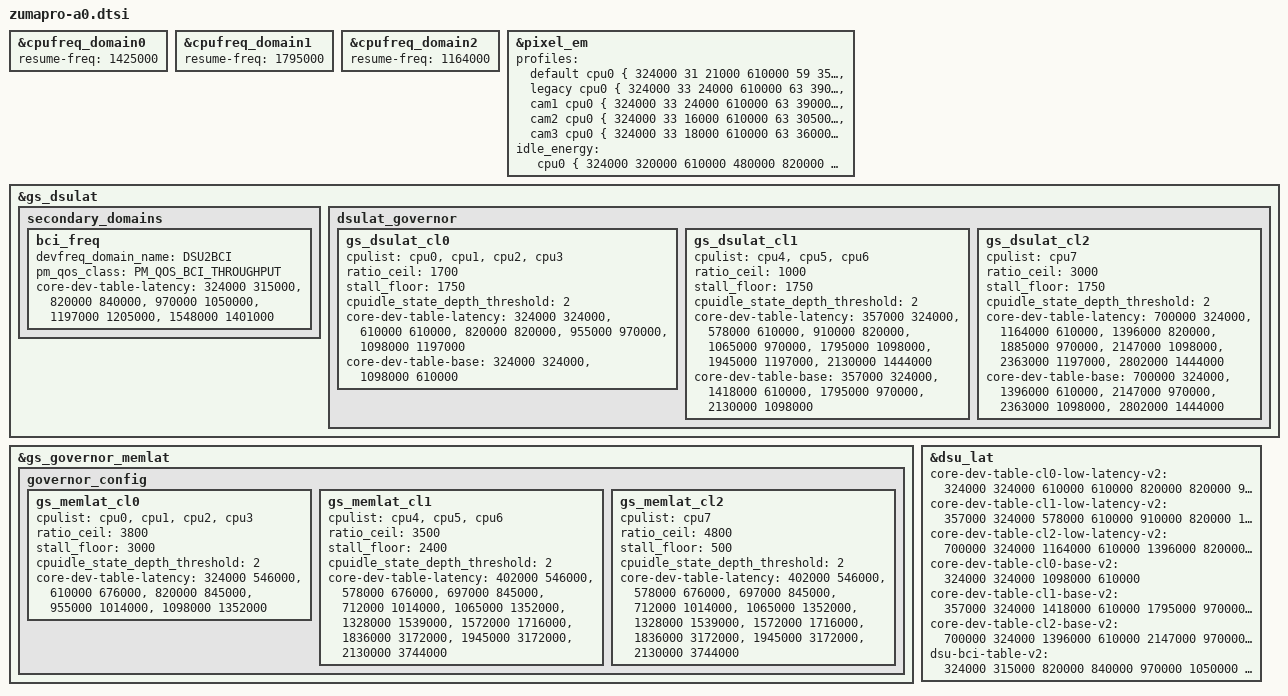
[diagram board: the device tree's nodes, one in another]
// SPDX-License-Identifier: GPL-2.0-only
/*
 * Copyright 2021 Google LLC.
 *
 */

#include "zumapro.dtsi"

&cpufreq_domain0 {
	resume-freq = <1425000>;
};

&cpufreq_domain1 {
	resume-freq = <1795000>;
};

&cpufreq_domain2 {
	resume-freq = <1164000>;
};

&pixel_em {
		profiles =
			"default
				cpu0 {
				324000 31 21000
				610000 59 35000
				820000 79 50000
				955000 92 60000
				1098000 106 74000
				1197000 116 85000
				1328000 128 99000
				1425000 138 116000
				1548000 150 131000
				1696000 164 156000
				1849000 179 193000
				1950000 189 226000
				}
				cpu4 {
				357000 100 53000
				578000 162 88000
				648000 182 99000
				787000 221 130000
				910000 256 162000
				1065000 299 205000
				1221000 343 263000
				1328000 373 308000
				1418000 399 347000
				1549000 435 400000
				1795000 504 526000
				1945000 547 660000
				2130000 599 843000
				2245000 632 1034000
				2367000 666 1221000
				2450000 689 1380000
				2600000 731 1722000
				}
				cpu7 {
				700000 226 250000
				1164000 378 536000
				1396000 429 732000
				1557000 522 912000
				1745000 572 1116000
				1885000 603 1286000
				1999000 674 1527000
				2147000 712 1929000
				2294000 746 2513000
				2363000 777 2808000
				2499000 822 3533000
				2687000 885 4854000
				2802000 923 5894000
				2914000 960 7122000
				2943000 970 7480000
				2970000 979 7828000
				3015000 994 8447000
				3105000 1024 9833000
				}
			",
			"legacy
				cpu0 {
				324000 33 24000
				610000 63 39000
				820000 84 56000
				955000 100 73000
				1098000 113 86000
				1197000 123 98000
				1328000 136 116000
				1425000 152 141000
				1548000 159 158000
				1696000 175 198000
				1849000 189 242000
				1950000 201 289000
				}
				cpu4 {
				357000 118 56000
				578000 170 84000
				648000 205 105000
				787000 212 107000
				910000 268 148000
				1065000 318 201000
				1221000 359 251000
				1328000 405 304000
				1418000 439 356000
				1549000 456 405000
				1795000 478 439000
				1945000 540 596000
				2130000 588 743000
				2245000 629 930000
				2367000 661 1122000
				2450000 692 1314000
				2600000 721 1515000
				}
				cpu7 {
				7000000 235 190000
				1164000 399 342000
				1396000 443 415000
				1557000 507 544000
				1745000 571 682000
				1885000 609 765000
				1999000 618 799000
				2147000 680 983000
				2294000 714 1134000
				2363000 748 1322000
				2499000 794 1481000
				2687000 850 1883000
				2802000 923 2377000
				2914000 972 2882000
				2943000 999 3465000
				2970000 1007 3954000
				3015000 1014 4200000
				3105000 1024 4500000
				}
			",
			"cam1
				cpu0 {
				324000 33 24000
				610000 63 39000
				820000 84 56000
				955000 100 73000
				1098000 113 86000
				1197000 123 98000
				1328000 136 116000
				1425000 152 141000
				1548000 159 158000
				1696000 175 198000
				1849000 189 242000
				1950000 201 289000
				}
				cpu4 {
				357000 118 56000
				578000 170 84000
				648000 205 105000
				787000 212 107000
				910000 268 148000
				1065000 318 201000
				1221000 359 251000
				1328000 405 304000
				1418000 439 356000
				1549000 456 405000
				1795000 478 439000
				1945000 540 596000
				2130000 588 743000
				2245000 629 930000
				2367000 661 1122000
				2450000 692 1314000
				2600000 721 1515000
				}
				cpu7 {
				700000 235 190000
				1164000 399 342000
				1396000 443 415000
				1557000 507 544000
				1745000 571 682000
				1885000 609 765000
				1999000 618 799000
				2147000 680 983000
				2294000 714 1134000
				2363000 748 1322000
				2499000 794 1481000
				2687000 850 1883000
				2802000 923 2377000
				2914000 972 2882000
				2943000 999 3465000
				2970000 1007 3954000
				3015000 1014 4200000
				3105000 1024 4500000
				}
			",
			"cam2
				cpu0 {
				324000 33 16000
				610000 63 30500
				820000 84 42000
				955000 100 54000
				1098000 113 204000
				1197000 123 266000
				1328000 136 318000
				1425000 177 356000
				1548000 189 406000
				1696000 198 466000
				1849000 208 528000
				1950000 213 568000
				}
				cpu4 {
				357000 79 41000
				578000 113 58000
				648000 137 66000
				787000 189 79000
				910000 230 95000
				1065000 242 118000
				1221000 252 280000
				1328000 270 318000
				1418000 293 358000
				1549000 304 418000
				1795000 319 528000
				1945000 360 598000
				2130000 392 758000
				2245000 419 898000
				2367000 441 1012000
				2450000 461 1156000
				2600000 600 1416000
				}
				cpu7 {
				700000 171 205000
				1164000 399 354000
				1396000 443 481000
				1557000 507 569000
				1745000 571 672000
				1885000 609 749000
				1999000 618 926000
				2147000 680 1157000
				2294000 714 1386000
				2363000 748 1527000
				2499000 794 1806000
				2687000 850 2192000
				2802000 923 2429000
				2914000 972 2658000
				2943000 999 2718000
				2970000 1007 2773000
				3015000 1014 2866000
				3105000 1024 3051000
				}
			",
			"cam3
				cpu0 {
				324000 33 18000
				610000 63 36000
				820000 84 53000
				955000 100 80000
				1098000 113 204000
				1197000 123 266000
				1328000 136 318000
				1425000 198 356000
				1548000 207 406000
				1696000 228 466000
				1849000 246 528000
				1950000 261 568000
				}
				cpu4 {
				357000 79 41000
				578000 113 58000
				648000 137 64000
				787000 189 79000
				910000 230 95000
				1065000 242 118000
				1221000 252 280000
				1328000 270 318000
				1418000 293 358000
				1549000 304 418000
				1795000 319 528000
				1945000 360 598000
				2130000 392 758000
				2245000 419 898000
				2367000 441 1012000
				2450000 461 1156000
				2600000 681 1416000
				}
				cpu7 {
				700000 233 206000
				1164000 399 354000
				1396000 443 481000
				1557000 507 569000
				1745000 571 672000
				1885000 609 749000
				1999000 618 926000
				2147000 680 1157000
				2294000 714 1386000
				2363000 748 1527000
				2499000 794 1806000
				2687000 850 2192000
				2802000 923 2429000
				2914000 972 2658000
				2943000 999 2718000
				2970000 1007 2773000
				3015000 1014 2866000
				3105000 1024 3051000
				}
			";
			idle_energy =
			"
			cpu0 {
			324000 320000
			610000 480000
			820000 480000
			955000 480000
			1098000 480000
			1197000 480000
			1328000 640000
			1425000 640000
			1548000 640000
			1696000 800000
			1849000 960000
			1950000 1280000
			}
			cpu4 {
			357000 1760000
			578000 2080000
			648000 1920000
			787000 2080000
			910000 2400000
			1065000 2560000
			1221000 2720000
			1328000 3040000
			1418000 3040000
			1549000 3520000
			1795000 4000000
			1945000 4480000
			2130000 6560000
			2245000 8000000
			2367000 9440000
			2450000 10880000
			2600000 12960000
			}
			cpu7 {
			700000 6240000
			1164000 9120000
			1396000 11840000
			1557000 12160000
			1745000 13760000
			1885000 15200000
			1999000 16160000
			2147000 19840000
			2294000 23360000
			2363000 28960000
			2499000 34400000
			2687000 36480000
			2802000 41600000
			2914000 45120000
			2943000 46720000
			2970000 47680000
			3015000 61280000
			3105000 62400000
			}
			";
};

&gs_dsulat {
	/* Linearly Dependent Domains. */
	secondary_domains {
		bci_freq {
			devfreq_domain_name = "DSU2BCI";
			pm_qos_class = <PM_QOS_BCI_THROUGHPUT>;
			core-dev-table-latency =
			/* DSU           BCI */
			<  324000        315000 >,
			<  820000        840000 >,
			<  970000       1050000 >,
			< 1197000       1205000 >,
			< 1548000       1401000 >;
		};
	};

	dsulat_governor {
		gs_dsulat_cl0 {
			cpulist = <&cpu0>, <&cpu1>, <&cpu2>, <&cpu3>;
			ratio_ceil = <1700>;
			stall_floor = <1750>;
			cpuidle_state_depth_threshold = <2>;

			core-dev-table-latency =
			/* CL0           DSU */
			<  324000        324000 >,
			<  610000        610000 >,
			<  820000        820000 >,
			<  955000        970000 >,
			< 1098000       1197000 >;

			core-dev-table-base =
			/* CL0           DSU */
			<  324000        324000 >,
			< 1098000        610000 >;
		};
		gs_dsulat_cl1 {
			cpulist = <&cpu4>, <&cpu5>, <&cpu6>;
			ratio_ceil = <1000>;
			stall_floor = <1750>;
			cpuidle_state_depth_threshold = <2>;

			core-dev-table-latency =
			/* CL1           DSU */
			<  357000        324000 >,
			<  578000        610000 >,
			<  910000        820000 >,
			< 1065000        970000 >,
			< 1795000       1098000 >,
			< 1945000       1197000 >,
			< 2130000       1444000 >;

			core-dev-table-base =
			/* CL1           DSU */
			<  357000        324000 >,
			< 1418000        610000 >,
			< 1795000        970000 >,
			< 2130000       1098000 >;

		};
		gs_dsulat_cl2 {
			cpulist = <&cpu7>;
			ratio_ceil = <3000>;
			stall_floor = <1750>;
			cpuidle_state_depth_threshold = <2>;

			core-dev-table-latency =
			/* CL2           DSU */
			<  700000        324000 >,
			< 1164000        610000 >,
			< 1396000        820000 >,
			< 1885000        970000 >,
			< 2147000       1098000 >,
			< 2363000       1197000 >,
			< 2802000       1444000 >;

			core-dev-table-base =
			/* CL2           DSU */
			<  700000        324000 >,
			< 1396000        610000 >,
			< 2147000        970000 >,
			< 2363000       1098000 >,
			< 2802000       1444000 >;
		};
	};
};

&gs_governor_memlat {
	governor_config {
		gs_memlat_cl0 {
			cpulist = <&cpu0>, <&cpu1>, <&cpu2>, <&cpu3>;
			ratio_ceil = <3800>;
			stall_floor = <3000>;
			cpuidle_state_depth_threshold = <2>;

			core-dev-table-latency =
			/* CL0         MIF */
				<  324000  546000 >,
				<  610000  676000 >,
				<  820000  845000 >,
				<  955000 1014000 >,
				< 1098000 1352000 >;
		};
		gs_memlat_cl1 {
			cpulist = <&cpu4>, <&cpu5>, <&cpu6>;
			ratio_ceil = <3500>;
			stall_floor = <2400>;
			cpuidle_state_depth_threshold = <2>;

			core-dev-table-latency =
			/* CL1         MIF */
				<  402000  546000 >,
				<  578000  676000 >,
				<  697000  845000 >,
				<  712000 1014000 >,
				< 1065000 1352000 >,
				< 1328000 1539000 >,
				< 1572000 1716000 >,
				< 1836000 3172000 >,
				< 1945000 3172000 >,
				< 2130000 3744000 >;
		};
		gs_memlat_cl2 {
			cpulist = <&cpu7>;
			ratio_ceil = <4800>;
			stall_floor = <500>;
			cpuidle_state_depth_threshold = <2>;

			core-dev-table-latency =
			/* CL2         MIF */
				<  402000  546000 >,
				<  578000  676000 >,
				<  697000  845000 >,
				<  712000 1014000 >,
				< 1065000 1352000 >,
				< 1328000 1539000 >,
				< 1572000 1716000 >,
				< 1836000 3172000 >,
				< 1945000 3172000 >,
				< 2130000 3744000 >;
		};
	};
};

&dsu_lat {
		core-dev-table-cl0-low-latency-v2 =
			/* CL0           DSU */
			<  324000        324000
			   610000        610000
			   820000        820000
			   955000        970000
			  1098000       1197000 >;

		core-dev-table-cl1-low-latency-v2 =
			/* CL1           DSU */
			<  357000        324000
			   578000        610000
			   910000        820000
			  1065000        970000
			  1795000       1098000
			  1945000       1197000
			  2130000       1444000 >;

		core-dev-table-cl2-low-latency-v2 =
			/* CL2           DSU */
			<  700000        324000
			  1164000        610000
			  1396000        820000
			  1885000        970000
			  2147000       1098000
			  2363000       1197000
			  2802000       1444000 >;

		core-dev-table-cl0-base-v2 =
			/* CL0           DSU */
			<  324000        324000
			  1098000        610000 >;

		core-dev-table-cl1-base-v2 =
			/* CL1           DSU */
			<  357000        324000
			  1418000        610000
			  1795000        970000
			  2130000       1098000 >;

		core-dev-table-cl2-base-v2 =
			/* CL2           DSU */
			<  700000        324000
			  1396000        610000
			  2147000        970000
			  2363000       1098000
			  2802000       1444000 >;

		dsu-bci-table-v2 =
			/* DSU           BCI */
			<  324000        315000
			   820000        840000
			   970000       1050000
			  1197000       1205000
			  1548000       1401000 >;
};
